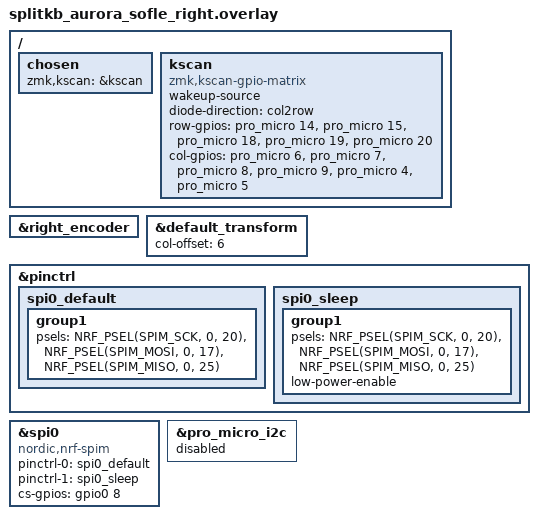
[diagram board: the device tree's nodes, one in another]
/*
 * Copyright (c) 2023 The ZMK Contributors
 *
 * SPDX-License-Identifier: MIT
 */

#include "splitkb_aurora_sofle.dtsi"

/ {
    chosen {
        zmk,kscan = &kscan;
    };

    kscan: kscan {
        compatible = "zmk,kscan-gpio-matrix";
        wakeup-source;

        diode-direction = "col2row";

        row-gpios
            = <&pro_micro 14 (GPIO_PULL_DOWN | GPIO_ACTIVE_HIGH)>
            , <&pro_micro 15 (GPIO_PULL_DOWN | GPIO_ACTIVE_HIGH)>
            , <&pro_micro 18 (GPIO_PULL_DOWN | GPIO_ACTIVE_HIGH)>
            , <&pro_micro 19 (GPIO_PULL_DOWN | GPIO_ACTIVE_HIGH)>
            , <&pro_micro 20 (GPIO_PULL_DOWN | GPIO_ACTIVE_HIGH)>
            ;

        col-gpios
            = <&pro_micro 6 GPIO_ACTIVE_HIGH>
            , <&pro_micro 7 GPIO_ACTIVE_HIGH>
            , <&pro_micro 8 GPIO_ACTIVE_HIGH>
            , <&pro_micro 9 GPIO_ACTIVE_HIGH>
            , <&pro_micro 4 GPIO_ACTIVE_HIGH>
            , <&pro_micro 5 GPIO_ACTIVE_HIGH>
            ;
    };
};

&right_encoder {
    status = "okay";
};

&default_transform {
    col-offset = <6>;
};

&pinctrl {
    spi0_default: spi0_default {
        group1 {
            psels = <NRF_PSEL(SPIM_SCK, 0, 20)>,
                <NRF_PSEL(SPIM_MOSI, 0, 17)>,
                <NRF_PSEL(SPIM_MISO, 0, 25)>;
        };
    };
    spi0_sleep: spi0_sleep {
        group1 {
            psels = <NRF_PSEL(SPIM_SCK, 0, 20)>,
                <NRF_PSEL(SPIM_MOSI, 0, 17)>,
                <NRF_PSEL(SPIM_MISO, 0, 25)>;
            low-power-enable;
        };
    };
};

nice_view_spi: &spi0 {
    compatible = "nordic,nrf-spim";
    pinctrl-0 = <&spi0_default>;
    pinctrl-1 = <&spi0_sleep>;
    pinctrl-names = "default", "sleep";
    cs-gpios = <&gpio0 8 GPIO_ACTIVE_HIGH>; //changed to n!n's GPIO8
};

&pro_micro_i2c {
    status = "disabled";
};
